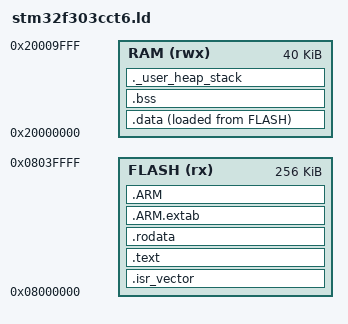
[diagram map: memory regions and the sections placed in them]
/* STM32F303CCT6 链接脚本 */
/* Flash: 256KB, RAM: 40KB */

/* 内存布局定义 */
MEMORY
{
    FLASH (rx)  : ORIGIN = 0x08000000, LENGTH = 256K
    RAM (rwx)   : ORIGIN = 0x20000000, LENGTH = 40K
}

/* 栈大小定义 */
_stack_size = 0x1000; /* 4KB 栈空间 */

/* 入口点 */
ENTRY(reset_handler)

/* 段定义 */
SECTIONS
{
    /* 中断向量表 */
    .isr_vector :
    {
        . = ALIGN(4);
        KEEP(*(.isr_vector))
        . = ALIGN(4);
    } >FLASH

    /* 程序代码段 */
    .text :
    {
        . = ALIGN(4);
        *(.text)
        *(.text*)
        *(.glue_7)
        *(.glue_7t)
        *(.eh_frame)
        
        KEEP (*(.init))
        KEEP (*(.fini))
        
        . = ALIGN(4);
        _etext = .;
    } >FLASH

    /* 只读数据段 */
    .rodata :
    {
        . = ALIGN(4);
        *(.rodata)
        *(.rodata*)
        . = ALIGN(4);
    } >FLASH

    /* ARM.extab段 */
    .ARM.extab :
    {
        *(.ARM.extab* .gnu.linkonce.armextab.*)
    } >FLASH
    
    .ARM :
    {
        __exidx_start = .;
        *(.ARM.exidx*)
        __exidx_end = .;
    } >FLASH

    /* 初始化数据段的加载地址 */
    _sidata = LOADADDR(.data);

    /* 初始化数据段 */
    .data :
    {
        . = ALIGN(4);
        _sdata = .;
        *(.data)
        *(.data*)
        . = ALIGN(4);
        _edata = .;
    } >RAM AT> FLASH

    /* 未初始化数据段 */
    .bss :
    {
        . = ALIGN(4);
        _sbss = .;
        __bss_start__ = _sbss;
        *(.bss)
        *(.bss*)
        *(COMMON)
        . = ALIGN(4);
        _ebss = .;
        __bss_end__ = _ebss;
    } >RAM

    /* 用户堆栈段 */
    ._user_heap_stack :
    {
        . = ALIGN(8);
        PROVIDE ( end = . );
        PROVIDE ( _end = . );
        . = . + _stack_size;
        . = ALIGN(8);
        _estack = .;
    } >RAM

    /* 移除调试信息 */
    /DISCARD/ :
    {
        libc.a ( * )
        libm.a ( * )
        libgcc.a ( * )
    }

    .ARM.attributes 0 : { *(.ARM.attributes) }
}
